AUTOSAR XML (schema 4-0-2)
standard types defined: UINT8, UINT16, UINT32, UINT64, SINT8, SINT16, SINT32, FLOAT32, FLOAT64, dtRef_const_VOID, dtRef_VOID
package /CalDataProvider/ComponentTypes
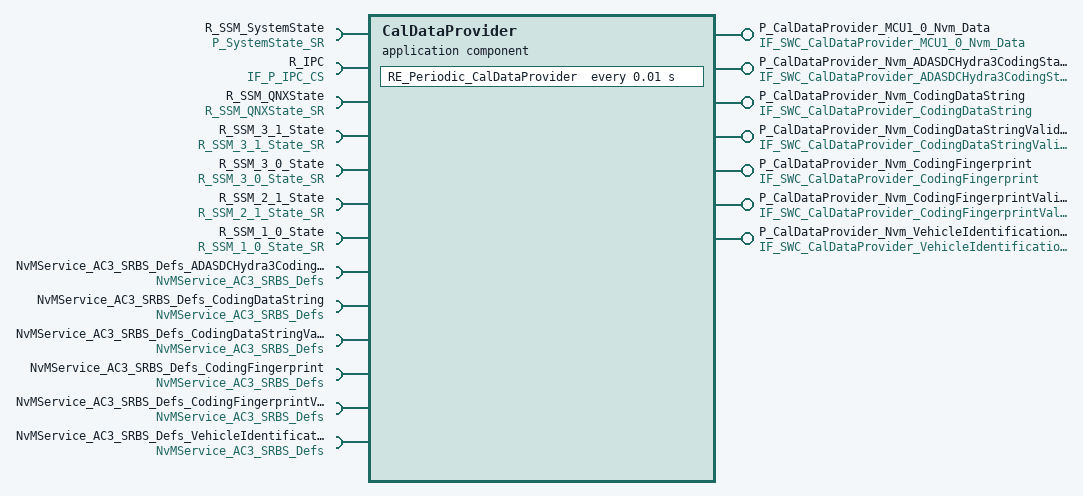
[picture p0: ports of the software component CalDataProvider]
  application sw component type CalDataProvider
    7 x provide port:
      P_CalDataProvider_MCU1_0_Nvm_Data: nonqueued-sender-com-spec{data-element=CalData_mcu1_0, init-value=constant-reference=init_CalData_mcu1_0}, provided-interface=IF_SWC_CalDataProvider_MCU1_0_Nvm_Data
      P_CalDataProvider_Nvm_ADASDCHydra3CodingState: server-com-spec{operation=IF_SWC_CalDataProvider_ADASDCHydra3CodingState/WriteBlock, queue-length=1}, provided-interface=IF_SWC_CalDataProvider_ADASDCHydra3CodingState
      P_CalDataProvider_Nvm_CodingDataString: server-com-spec{operation=IF_SWC_CalDataProvider_CodingDataString/WriteBlock, queue-length=1}, provided-interface=IF_SWC_CalDataProvider_CodingDataString
      P_CalDataProvider_Nvm_CodingDataStringValidation: server-com-spec{operation=IF_SWC_CalDataProvider_CodingDataStringValidation/WriteBlock, queue-length=1}, provided-interface=IF_SWC_CalDataProvider_CodingDataStringValidation
      P_CalDataProvider_Nvm_CodingFingerprint: server-com-spec{operation=IF_SWC_CalDataProvider_CodingFingerprint/WriteBlock, queue-length=1}, provided-interface=IF_SWC_CalDataProvider_CodingFingerprint
      P_CalDataProvider_Nvm_CodingFingerprintValidation: server-com-spec{operation=IF_SWC_CalDataProvider_CodingFingerprintValidation/WriteBlock, queue-length=1}, provided-interface=IF_SWC_CalDataProvider_CodingFingerprintValidation
      P_CalDataProvider_Nvm_VehicleIdentificationNumber: server-com-spec{operation=IF_SWC_CalDataProvider_VehicleIdentificationNumber/WriteBlock, queue-length=1}, provided-interface=IF_SWC_CalDataProvider_VehicleIdentificationNumber
    13 x require port:
      R_SSM_SystemState: nonqueued-receiver-com-spec{data-element=SystemState, init-value=constant-reference=init_SystemState}, required-interface=P_SystemState_SR
      R_IPC: client-com-spec=IPC_Write_v, required-interface=IF_P_IPC_CS
      R_SSM_QNXState: nonqueued-receiver-com-spec{data-element=State_QNX, init-value=constant-reference=init_State_QNX}, required-interface=R_SSM_QNXState_SR
      R_SSM_3_1_State: nonqueued-receiver-com-spec{data-element=State_3_1, init-value=constant-reference=init_State_3_1}, required-interface=R_SSM_3_1_State_SR
      R_SSM_3_0_State: nonqueued-receiver-com-spec{data-element=State_3_0, init-value=constant-reference=init_State_3_0}, required-interface=R_SSM_3_0_State_SR
      R_SSM_2_1_State: required-interface=R_SSM_2_1_State_SR
        required-com-specs:
          data-element=State_2_1, init-value=constant-reference=init_State_2_1
          data-element=State_2_0, init-value=constant-reference=init_State_2_0
      R_SSM_1_0_State: nonqueued-receiver-com-spec{data-element=State_1_0, init-value=constant-reference=init_State_1_0}, required-interface=R_SSM_1_0_State_SR
      NvMService_AC3_SRBS_Defs_ADASDCHydra3CodingState: client-com-spec=NvMService_AC3_SRBS_Defs/WriteBlock, required-interface=NvMService_AC3_SRBS_Defs
      NvMService_AC3_SRBS_Defs_CodingDataString: client-com-spec=NvMService_AC3_SRBS_Defs/WriteBlock, required-interface=NvMService_AC3_SRBS_Defs
      NvMService_AC3_SRBS_Defs_CodingDataStringValidation: client-com-spec=NvMService_AC3_SRBS_Defs/WriteBlock, required-interface=NvMService_AC3_SRBS_Defs
      NvMService_AC3_SRBS_Defs_CodingFingerprint: client-com-spec=NvMService_AC3_SRBS_Defs/WriteBlock, required-interface=NvMService_AC3_SRBS_Defs
      NvMService_AC3_SRBS_Defs_CodingFingerprintValidation: client-com-spec=NvMService_AC3_SRBS_Defs/WriteBlock, required-interface=NvMService_AC3_SRBS_Defs
      NvMService_AC3_SRBS_Defs_VehicleIdentificationNumber: client-com-spec=NvMService_AC3_SRBS_Defs/WriteBlock, required-interface=NvMService_AC3_SRBS_Defs
    behavior CalDataProvider_InternalBehavior: handle-termination-and-restart=NO-SUPPORT
      ar-typed-per-instance-memorys:
        6 x data, all with sw-calibration-access=READ-WRITE:
          ADASDCHydra3CodingState_MirrorBlock: type=UINT8
          CodingDataString_MirrorBlock: type=Dcm_Data256ByteType
          CodingDataStringValidation_MirrorBlock: type=UINT8
          CodingFingerprint_MirrorBlock: type=Dcm_Data30ByteType
          CodingFingerprintValidation_MirrorBlock: type=UINT8
          VehicleIdentificationNumber_MirrorBlock: type=Dcm_Data17ByteType
      timing event TMT_RE_Periodic_CalDataProvider: start-on-event=RE_Periodic_CalDataProvider, period=0.01
      init event InitEvent: start-on-event=RE_CalDataProvider_Init
      6 x operation invoked event:
        OIT_RE_CalDataProvider_Nvm_ADASDCHydra3CodingState_P_CalDataProvider_Nvm_ADASDCHydra3CodingState_WriteBlock: start-on-event=RE_CalDataProvider_Nvm_ADASDCHydra3CodingState, operation=P_CalDataProvider_Nvm_ADASDCHydra3CodingState.WriteBlock
        OIT_RE_CalDataProvider_Nvm_CodingDataString_P_CalDataProvider_Nvm_CodingDataString_WriteBlock: start-on-event=RE_CalDataProvider_Nvm_CodingDataString, operation=P_CalDataProvider_Nvm_CodingDataString.WriteBlock
        OIT_RE_CalDataProvider_Nvm_CodingDataStringValidation_P_CalDataProvider_Nvm_CodingDataStringValidation_WriteBlock: start-on-event=RE_CalDataProvider_Nvm_CodingDataStringValidation, operation=P_CalDataProvider_Nvm_CodingDataStringValidation.WriteBlock
        OIT_RE_CalDataProvider_Nvm_CodingFingerprint_P_CalDataProvider_Nvm_CodingFingerprint_WriteBlock: start-on-event=RE_CalDataProvider_Nvm_CodingFingerprint, operation=P_CalDataProvider_Nvm_CodingFingerprint.WriteBlock
        OIT_RE_CalDataProvider_Nvm_CodingFingerprintValidation_P_CalDataProvider_Nvm_CodingFingerprintValidation_WriteBlock: start-on-event=RE_CalDataProvider_Nvm_CodingFingerprintValidation, operation=P_CalDataProvider_Nvm_CodingFingerprintValidation.WriteBlock
        OIT_RE_CalDataProvider_Nvm_VehicleIdentificationNumber_P_CalDataProvider_Nvm_VehicleIdentificationNumber_WriteBlock: start-on-event=RE_CalDataProvider_Nvm_VehicleIdentificationNumber, operation=P_CalDataProvider_Nvm_VehicleIdentificationNumber.WriteBlock
      port-api-options:
        enable-take-address=false, indirect-api=false, port=NvMService_AC3_SRBS_Defs_ADASDCHydra3CodingState
        enable-take-address=false, indirect-api=false, port=NvMService_AC3_SRBS_Defs_CodingDataString
        enable-take-address=false, indirect-api=false, port=NvMService_AC3_SRBS_Defs_CodingDataStringValidation
        enable-take-address=false, indirect-api=false, port=NvMService_AC3_SRBS_Defs_CodingFingerprint
        enable-take-address=false, indirect-api=false, port=NvMService_AC3_SRBS_Defs_CodingFingerprintValidation
        enable-take-address=false, indirect-api=false, port=NvMService_AC3_SRBS_Defs_VehicleIdentificationNumber
        enable-take-address=false, indirect-api=false, port=P_CalDataProvider_MCU1_0_Nvm_Data
        enable-take-address=false, indirect-api=false, port=P_CalDataProvider_Nvm_ADASDCHydra3CodingState
        enable-take-address=false, indirect-api=false, port=P_CalDataProvider_Nvm_CodingDataString
        enable-take-address=false, indirect-api=false, port=P_CalDataProvider_Nvm_CodingDataStringValidation
        enable-take-address=false, indirect-api=false, port=P_CalDataProvider_Nvm_CodingFingerprint
        enable-take-address=false, indirect-api=false, port=P_CalDataProvider_Nvm_CodingFingerprintValidation
        enable-take-address=false, indirect-api=false, port=P_CalDataProvider_Nvm_VehicleIdentificationNumber
        enable-take-address=false, indirect-api=false, port=R_IPC
        enable-take-address=false, indirect-api=false, port=R_SSM_1_0_State
        enable-take-address=false, indirect-api=false, port=R_SSM_2_1_State
        enable-take-address=false, indirect-api=false, port=R_SSM_3_0_State
        enable-take-address=false, indirect-api=false, port=R_SSM_3_1_State
        enable-take-address=false, indirect-api=false, port=R_SSM_QNXState
        enable-take-address=false, indirect-api=false, port=R_SSM_SystemState
      8 x runnable:
        RE_Periodic_CalDataProvider  # Periodic Runnable of Satellite
          data-receive-point-by-arguments:
            7 x access:
              REC_R_SSM_SystemState_SystemState: accessed-variable=R_SSM_SystemState.SystemState
              REC_R_SSM_QNXState_State_QNX: accessed-variable=R_SSM_QNXState.State_QNX
              REC_R_SSM_3_1_State_State_3_1: accessed-variable=R_SSM_3_1_State.State_3_1
              REC_R_SSM_3_0_State_State_3_0: accessed-variable=R_SSM_3_0_State.State_3_0
              REC_R_SSM_2_1_State_State_2_1: accessed-variable=R_SSM_2_1_State.State_2_1
              REC_R_SSM_2_1_State_State_2_0: accessed-variable=R_SSM_2_1_State.State_2_0
              REC_R_SSM_1_0_State_State_1_0: accessed-variable=R_SSM_1_0_State.State_1_0
          data-send-points:
            access SEND_P_CalDataProvider_MCU1_0_Nvm_Data_CalData_mcu1_0: accessed-variable=P_CalDataProvider_MCU1_0_Nvm_Data.CalData_mcu1_0
          6 x parameter access:
            PA_ADASDCHydra3CodingState_DefaultValue: accessed-parameter=ADASDCHydra3CodingState_DefaultValue
            PA_CodingDataString_DefaultValue: accessed-parameter=CodingDataString_DefaultValue
            PA_CodingDataStringValidation_DefaultValue: accessed-parameter=CodingDataStringValidation_DefaultValue
            PA_CodingFingerprint_DefaultValue: accessed-parameter=CodingFingerprint_DefaultValue
            PA_CodingFingerprintValidation_DefaultValue: accessed-parameter=CodingFingerprintValidation_DefaultValue
            PA_VehicleIdentificationNumber_DefaultValue: accessed-parameter=VehicleIdentificationNumber_DefaultValue
          sync call SC_R_IPC_IPC_Write_v: operation=R_IPC.IPC_Write_v, timeout=0
        RE_CalDataProvider_Init
          6 x parameter access:
            PA_ADASDCHydra3CodingState_DefaultValue: accessed-parameter=ADASDCHydra3CodingState_DefaultValue
            PA_CodingDataString_DefaultValue: accessed-parameter=CodingDataString_DefaultValue
            PA_CodingDataStringValidation_DefaultValue: accessed-parameter=CodingDataStringValidation_DefaultValue
            PA_CodingFingerprint_DefaultValue: accessed-parameter=CodingFingerprint_DefaultValue
            PA_CodingFingerprintValidation_DefaultValue: accessed-parameter=CodingFingerprintValidation_DefaultValue
            PA_VehicleIdentificationNumber_DefaultValue: accessed-parameter=VehicleIdentificationNumber_DefaultValue
        RE_CalDataProvider_Nvm_ADASDCHydra3CodingState
          6 x parameter access:
            PA_ADASDCHydra3CodingState_DefaultValue: accessed-parameter=ADASDCHydra3CodingState_DefaultValue
            PA_CodingDataString_DefaultValue: accessed-parameter=CodingDataString_DefaultValue
            PA_CodingDataStringValidation_DefaultValue: accessed-parameter=CodingDataStringValidation_DefaultValue
            PA_CodingFingerprint_DefaultValue: accessed-parameter=CodingFingerprint_DefaultValue
            PA_CodingFingerprintValidation_DefaultValue: accessed-parameter=CodingFingerprintValidation_DefaultValue
            PA_VehicleIdentificationNumber_DefaultValue: accessed-parameter=VehicleIdentificationNumber_DefaultValue
        RE_CalDataProvider_Nvm_CodingDataString
          6 x parameter access:
            PA_ADASDCHydra3CodingState_DefaultValue: accessed-parameter=ADASDCHydra3CodingState_DefaultValue
            PA_CodingDataString_DefaultValue: accessed-parameter=CodingDataString_DefaultValue
            PA_CodingDataStringValidation_DefaultValue: accessed-parameter=CodingDataStringValidation_DefaultValue
            PA_CodingFingerprint_DefaultValue: accessed-parameter=CodingFingerprint_DefaultValue
            PA_CodingFingerprintValidation_DefaultValue: accessed-parameter=CodingFingerprintValidation_DefaultValue
            PA_VehicleIdentificationNumber_DefaultValue: accessed-parameter=VehicleIdentificationNumber_DefaultValue
        RE_CalDataProvider_Nvm_CodingDataStringValidation
          6 x parameter access:
            PA_ADASDCHydra3CodingState_DefaultValue: accessed-parameter=ADASDCHydra3CodingState_DefaultValue
            PA_CodingDataString_DefaultValue: accessed-parameter=CodingDataString_DefaultValue
            PA_CodingDataStringValidation_DefaultValue: accessed-parameter=CodingDataStringValidation_DefaultValue
            PA_CodingFingerprint_DefaultValue: accessed-parameter=CodingFingerprint_DefaultValue
            PA_CodingFingerprintValidation_DefaultValue: accessed-parameter=CodingFingerprintValidation_DefaultValue
            PA_VehicleIdentificationNumber_DefaultValue: accessed-parameter=VehicleIdentificationNumber_DefaultValue
        RE_CalDataProvider_Nvm_CodingFingerprint
          6 x parameter access:
            PA_ADASDCHydra3CodingState_DefaultValue: accessed-parameter=ADASDCHydra3CodingState_DefaultValue
            PA_CodingDataString_DefaultValue: accessed-parameter=CodingDataString_DefaultValue
            PA_CodingDataStringValidation_DefaultValue: accessed-parameter=CodingDataStringValidation_DefaultValue
            PA_CodingFingerprint_DefaultValue: accessed-parameter=CodingFingerprint_DefaultValue
            PA_CodingFingerprintValidation_DefaultValue: accessed-parameter=CodingFingerprintValidation_DefaultValue
            PA_VehicleIdentificationNumber_DefaultValue: accessed-parameter=VehicleIdentificationNumber_DefaultValue
        RE_CalDataProvider_Nvm_CodingFingerprintValidation
          6 x parameter access:
            PA_ADASDCHydra3CodingState_DefaultValue: accessed-parameter=ADASDCHydra3CodingState_DefaultValue
            PA_CodingDataString_DefaultValue: accessed-parameter=CodingDataString_DefaultValue
            PA_CodingDataStringValidation_DefaultValue: accessed-parameter=CodingDataStringValidation_DefaultValue
            PA_CodingFingerprint_DefaultValue: accessed-parameter=CodingFingerprint_DefaultValue
            PA_CodingFingerprintValidation_DefaultValue: accessed-parameter=CodingFingerprintValidation_DefaultValue
            PA_VehicleIdentificationNumber_DefaultValue: accessed-parameter=VehicleIdentificationNumber_DefaultValue
        RE_CalDataProvider_Nvm_VehicleIdentificationNumber
          6 x parameter access:
            PA_ADASDCHydra3CodingState_DefaultValue: accessed-parameter=ADASDCHydra3CodingState_DefaultValue
            PA_CodingDataString_DefaultValue: accessed-parameter=CodingDataString_DefaultValue
            PA_CodingDataStringValidation_DefaultValue: accessed-parameter=CodingDataStringValidation_DefaultValue
            PA_CodingFingerprint_DefaultValue: accessed-parameter=CodingFingerprint_DefaultValue
            PA_CodingFingerprintValidation_DefaultValue: accessed-parameter=CodingFingerprintValidation_DefaultValue
            PA_VehicleIdentificationNumber_DefaultValue: accessed-parameter=VehicleIdentificationNumber_DefaultValue
      6 x swc service dependency:
        ADASDCHydra3CodingState: assigned-ports=role-based-port-assignment={port-prototype=NvMService_AC3_SRBS_Defs_ADASDCHydra3CodingState, role=NvMService_AC3_SRBS_Defs_ADASDCHydra3CodingState}
          assigned-datas:
            role=ramBlock, used-data-element=ADASDCHydra3CodingState_MirrorBlock
            role=defaultValue, used-parameter-element=ADASDCHydra3CodingState_DefaultValue
          service-needs:
            nv block needs ADASDCHydra3CodingState: calc-ram-block-crc=true, check-static-block-id=false, n-data-sets=0, ram-block-status-control=API, readonly=false, reliability=NO-PROTECTION, resistant-to-changed-sw=true, restore-at-start=true, store-at-shutdown=true, store-cyclic=false, store-emergency=false, store-immediate=false, use-auto-validation-at-shut-down=false, use-crc-comp-mechanism=true, write-only-once=false, write-verification=false
        CodingDataString: assigned-ports=role-based-port-assignment={port-prototype=NvMService_AC3_SRBS_Defs_CodingDataString, role=NvMService_AC3_SRBS_Defs_CodingDataString}
          assigned-datas:
            role=ramBlock, used-data-element=CodingDataString_MirrorBlock
            role=defaultValue, used-parameter-element=CodingDataString_DefaultValue
          service-needs:
            nv block needs CodingDataString: calc-ram-block-crc=true, check-static-block-id=false, n-data-sets=0, ram-block-status-control=API, readonly=false, reliability=NO-PROTECTION, resistant-to-changed-sw=true, restore-at-start=true, store-at-shutdown=true, store-cyclic=false, store-emergency=false, store-immediate=false, use-auto-validation-at-shut-down=false, use-crc-comp-mechanism=true, write-only-once=false, write-verification=false
        CodingDataStringValidation: assigned-ports=role-based-port-assignment={port-prototype=NvMService_AC3_SRBS_Defs_CodingDataStringValidation, role=NvMService_AC3_SRBS_Defs_CodingDataStringValidation}
          assigned-datas:
            role=ramBlock, used-data-element=CodingDataStringValidation_MirrorBlock
            role=defaultValue, used-parameter-element=CodingDataStringValidation_DefaultValue
          service-needs:
            nv block needs CodingDataStringValidation: calc-ram-block-crc=true, check-static-block-id=false, n-data-sets=0, ram-block-status-control=API, readonly=false, reliability=NO-PROTECTION, resistant-to-changed-sw=true, restore-at-start=true, store-at-shutdown=true, store-cyclic=false, store-emergency=false, store-immediate=false, use-auto-validation-at-shut-down=false, use-crc-comp-mechanism=true, write-only-once=false, write-verification=false
        CodingFingerprint: assigned-ports=role-based-port-assignment={port-prototype=NvMService_AC3_SRBS_Defs_CodingFingerprint, role=NvMService_AC3_SRBS_Defs_CodingFingerprint}
          assigned-datas:
            role=ramBlock, used-data-element=CodingFingerprint_MirrorBlock
            role=defaultValue, used-parameter-element=CodingFingerprint_DefaultValue
          service-needs:
            nv block needs CodingFingerprint: calc-ram-block-crc=true, check-static-block-id=false, n-data-sets=0, ram-block-status-control=API, readonly=false, reliability=NO-PROTECTION, resistant-to-changed-sw=true, restore-at-start=true, store-at-shutdown=true, store-cyclic=false, store-emergency=false, store-immediate=false, use-auto-validation-at-shut-down=false, use-crc-comp-mechanism=true, write-only-once=false, write-verification=false
        CodingFingerprintValidation: assigned-ports=role-based-port-assignment={port-prototype=NvMService_AC3_SRBS_Defs_CodingFingerprintValidation, role=NvMService_AC3_SRBS_Defs_CodingFingerprintValidation}
          assigned-datas:
            role=ramBlock, used-data-element=CodingFingerprintValidation_MirrorBlock
            role=defaultValue, used-parameter-element=CodingFingerprintValidation_DefaultValue
          service-needs:
            nv block needs CodingFingerprintValidation: calc-ram-block-crc=true, check-static-block-id=false, n-data-sets=0, ram-block-status-control=API, readonly=false, reliability=NO-PROTECTION, resistant-to-changed-sw=true, restore-at-start=true, store-at-shutdown=true, store-cyclic=false, store-emergency=false, store-immediate=false, use-auto-validation-at-shut-down=false, use-crc-comp-mechanism=true, write-only-once=false, write-verification=false
        VehicleIdentificationNumber: assigned-ports=role-based-port-assignment={port-prototype=NvMService_AC3_SRBS_Defs_VehicleIdentificationNumber, role=NvMService_AC3_SRBS_Defs_VehicleIdentificationNumber}
          assigned-datas:
            role=ramBlock, used-data-element=VehicleIdentificationNumber_MirrorBlock
            role=defaultValue, used-parameter-element=VehicleIdentificationNumber_DefaultValue
          service-needs:
            nv block needs VehicleIdentificationNumber: calc-ram-block-crc=true, check-static-block-id=false, n-data-sets=0, ram-block-status-control=API, readonly=false, reliability=NO-PROTECTION, resistant-to-changed-sw=true, restore-at-start=true, store-at-shutdown=true, store-cyclic=false, store-emergency=false, store-immediate=false, use-auto-validation-at-shut-down=false, use-crc-comp-mechanism=true, write-only-once=false, write-verification=false
      shared-parameters:
        6 x parameter data prototype, all with sw-calibration-access=READ-ONLY:
          ADASDCHydra3CodingState_DefaultValue: type=UINT8, init-value=0
          CodingDataString_DefaultValue: type=Dcm_Data256ByteType, init-value=[0, 0, 0, 0, 0, 0, 0, 0, 0, 0, 0, 0, 1, 0, 1, 1, 0, 1, 1, 0, 0, 0, 1, 0, 1, 1, 1, 0, 0, 0, 0, 0, 0, 0, 0, 0, 0, 0, 0, 0, 0, 0, 0, 0, 0, 0, 22, 99, 8, 40, 0, 0, 0, 20, 0, 0, 0, 0, 0, 0, 0, 0, 0, 0, 0, 0, 0, 0, 0, 0, 0, 0, 0, 0, 0, 0, 0, 0, 0, 0, 0, 0, 0, 0, 0, 0, 0, 0, 0, 0, 0, 0, 0, 0, 0, 0, 0, 0, 0, 0, 0, 0, 0, 0, 0, 0, 0, 0, 0, 0, 0, 0, 0, 0, 0, 0, 0, 0, 0, 0, 0, 0, 0, 0, 0, 0, 0, 0, 0, 0, 0, 0, 0, 0, 0, 0, 0, 0, 0, 0, 0, 0, 0, 0, 0, 0, 0, 0, 0, 0, 0, 0, 0, 0, 0, 0, 0, 0, 0, 0, 0, 0, 0, 0, 0, 0, 0, 0, 0, 0, 0, 0, 0, 0, 0, 0, 0, 0, 0, 0, 0, 0, 0, 0, 0, 0, 0, 0, 0, 0, 0, 0, 0, 0, 0, 0, 0, 0, 0, 0, 0, 0, 0, 0, 0, 0, 0, 0, 0, 0, 0, 0, 0, 0, 0, 0, 0, 0, 0, 0, 0, 0, 0, 0, 0, 0, 0, 0, 0, 0, 0, 0, 0, 0, 0, 0, 0, 0, 0, 0, 0, 0, 0, 0, 0, 0, 0, 0, 0, 0, 0, 0, 0, 0, 0, 0]
          CodingDataStringValidation_DefaultValue: type=UINT8, init-value=0
          CodingFingerprint_DefaultValue: type=Dcm_Data30ByteType, init-value=30 x 0
          CodingFingerprintValidation_DefaultValue: type=UINT8, init-value=0
          VehicleIdentificationNumber_DefaultValue: type=Dcm_Data17ByteType, init-value=17 x 0
  swc implementation CalDataProvider_Implementation: programming-language=C, vendor-id=0, behavior=CalDataProvider_InternalBehavior
    code-descriptors:
      code Default: artifact-descriptors=autosar-engineering-object={short-label=Default, category=SWSRC}
package /CalDataProvider/Constant
  7 x constant specification:
    init_CalData_mcu1_0: value-spec=fields=[0, 0, [0, 0, 0, 0, 0, 0, 0, 0, 0, 0, 0, 0, 1, 0, 1, 1, 0, 1, 1, 0, 0, 0, 1, 0, 1, 1, 1, 0, 0, 0, 0, 0, 0, 0, 0, 0, 0, 0, 0, 0, 0, 0, 0, 0, 0, 0, 22, 99, 8, 40, 0, 0, 0, 20, 0, 0, 0, 0, 0, 0, 0, 0, 0, 0, 0, 0, 0, 0, 0, 0, 0, 0, 0, 0, 0, 0, 0, 0, 0, 0, 0, 0, 0, 0, 0, 0, 0, 0, 0, 0, 0, 0, 0, 0, 0, 0, 0, 0, 0, 0, 0, 0, 0, 0, 0, 0, 0, 0, 0, 0, 0, 0, 0, 0, 0, 0, 0, 0, 0, 0, 0, 0, 0, 0, 0, 0, 0, 0, 0, 0, 0, 0, 0, 0, 0, 0, 0, 0, 0, 0, 0, 0, 0, 0, 0, 0, 0, 0, 0, 0, 0, 0, 0, 0, 0, 0, 0, 0, 0, 0, 0, 0, 0, 0, 0, 0, 0, 0, 0, 0, 0, 0, 0, 0, 0, 0, 0, 0, 0, 0, 0, 0, 0, 0, 0, 0, 0, 0, 0, 0, 0, 0, 0, 0, 0, 0, 0, 0, 0, 0, 0, 0, 0, 0, 0, 0, 0, 0, 0, 0, 0, 0, 0, 0, 0, 0, 0, 0, 0, 0, 0, 0, 0, 0, 0, 0, 0, 0, 0, 0, 0, 0, 0, 0, 0, 0, 0, 0, 0, 0, 0, 0, 0, 0, 0, 0, 0, 0, 0, 0, 0, 0, 0, 0, 0, 0], 0, 30 x 0, 0, 17 x 0, 0]
    init_State_QNX: value-spec=fields=[0, [0, 0, 0]]
    init_State_3_1: value-spec=fields=[0, [0, 0]]
    init_State_3_0: value-spec=fields=[0, [0, 0]]
    init_State_2_1: value-spec=fields=[0, 6 x 0]
    init_State_2_0: value-spec=fields=[0, [0, 0]]
    init_State_1_0: value-spec=fields=[0, [0, 0, 0]]
package /CalDataProvider/ImplementationDataTypes
  28 x impl type, all with type-emitter=RTE:
    BOOL: implementation-data-type=boolean
    SSM_CoreSlaveCoreStateDef: compu {0=SSM_SlaveCore_State_Unknown, 1=SSM_SlaveCore_State_BSP_Booting, 2=SSM_SlaveCore_State_BSP_Init_Done, 3=SSM_SlaveCore_State_Calibrated, 4=SSM_SlaveCore_State_AppInitialized, 5=SSM_SlaveCore_State_Running, 6=SSM_SlaveCore_State_MAX}, implementation-data-type=uint32
    SSM_SystemStateDef: compu {0=SSM_STATE_BOOTING, 1=SSM_STATE_IPCREADY, 2=SSM_STATE_RUNNING, 3=SSM_STATE_DEGRADED, 4=SSM_STATE_POWERINGDOWN, 5=SSM_STATE_OFF, 6=SSM_STATE_MAX}, implementation-data-type=uint32
    SSM_DegradedState: compu {0=SSM_DEGRADEDSTATE_MAX}, implementation-data-type=uint32
    SSM_ApplicationStatus: compu {0=SSM_APPSTATE_UNINIT, 1=SSM_APPSTATE_INIT, 2=SSM_APPSTATE_RUNNING, 3=SSM_APPSTATE_DEGRADED, 4=SSM_APPSTATE_STOPPED, 5=SSM_APPSTATE_MAX}, implementation-data-type=uint32
    SSM_MCU_QNX_Applications: compu {0=SSM_MCU_QNX_Application_ErrorMgr, 1=SSM_MCU_QNX_Application_PLD, 2=SSM_MCU_QNX_Application_MAX}, implementation-data-type=uint32
    SSM_MCU_3_1_Applications: compu {0=SSM_MCU_3_1_Application_ErrorMgr, 1=SSM_MCU_3_1_Application_MAX}, implementation-data-type=uint32
    SSM_MCU_3_0_Applications: compu {0=SSM_MCU_3_0_Application_ErrorMgr, 1=SSM_MCU_3_0_Application_USS, 2=SSM_MCU_3_0_Application_APA, 3=SSM_MCU_3_0_Application_CD, 4=SSM_MCU_3_0_Application_FUSION, 5=SSM_MCU_3_0_Application_MAX}, implementation-data-type=uint32
    SSM_MCU_2_1_Applications: compu {0=SSM_MCU_2_1_Application_ErrorMgr, 1=SSM_MCU_2_1_Application_HSF, 2=SSM_MCU_2_1_Application_KM, 3=SSM_MCU_2_1_Application_APStateMachine, 4=SSM_MCU_2_1_Application_DMS, 5=SSM_MCU_2_1_Application_MAX}, implementation-data-type=uint32
    SSM_MCU_2_0_Applications: compu {0=SSM_MCU_2_0_Application_ErrorMgr, 1=SSM_MCU_2_0_Application_MAX}, implementation-data-type=uint32
    SSM_MCU_1_0_Applications: compu {0=SSM_MCU_1_0_Application_VehInpAdapter, 1=SSM_MCU_1_0_Application_VehOptAdapter, 2=SSM_MCU_1_0_Application_MAX}, implementation-data-type=uint32
    SSM_MCU_QNX_LocalAppStatus_Arr: category=ARRAY
      element Elem_SSM_ApplicationStatus: array-size=3, array-size-semantics=FIXED-SIZE, implementation-data-type=SSM_ApplicationStatus
    SSM_MCU_3_1_LocalAppStatus_Arr: category=ARRAY
      element Elem_SSM_ApplicationStatus: array-size=2, array-size-semantics=FIXED-SIZE, implementation-data-type=SSM_ApplicationStatus
    SSM_MCU_3_0__LocalAppStatus_Arr: category=ARRAY
      element Elem_SSM_ApplicationStatus: array-size=6, array-size-semantics=FIXED-SIZE, implementation-data-type=SSM_ApplicationStatus
    SSM_MCU_2_1_LocalAppStatus_Arr: category=ARRAY
      element Elem_SSM_ApplicationStatus: array-size=6, array-size-semantics=FIXED-SIZE, implementation-data-type=SSM_ApplicationStatus
    SSM_MCU_2_0_LocalAppStatus_Arr: category=ARRAY
      element Elem_SSM_ApplicationStatus: array-size=2, array-size-semantics=FIXED-SIZE, implementation-data-type=SSM_ApplicationStatus
    SSM_MCU_1_0_LocalAppStatus_Arr: category=ARRAY
      element Elem_SSM_ApplicationStatus: array-size=3, array-size-semantics=FIXED-SIZE, implementation-data-type=SSM_ApplicationStatus
    SSM_QNX_CoreStatus: category=STRUCTURE
      element CoreStatus: implementation-data-type=SSM_CoreSlaveCoreStateDef
      element LocalAppStatus: implementation-data-type=SSM_MCU_QNX_LocalAppStatus_Arr
    SSM_3_1_CoreStatus: category=STRUCTURE
      element CoreStatus: implementation-data-type=SSM_CoreSlaveCoreStateDef
      element LocalAppStatus: implementation-data-type=SSM_MCU_3_1_LocalAppStatus_Arr
    SSM_3_0_CoreStatus: category=STRUCTURE
      element CoreStatus: implementation-data-type=SSM_CoreSlaveCoreStateDef
      element LocalAppStatus: implementation-data-type=SSM_MCU_2_0_LocalAppStatus_Arr
    SSM_2_1_CoreStatus: category=STRUCTURE
      element CoreStatus: implementation-data-type=SSM_CoreSlaveCoreStateDef
      element LocalAppStatus: implementation-data-type=SSM_MCU_2_1_LocalAppStatus_Arr
    SSM_2_0_CoreStatus: category=STRUCTURE
      element CoreStatus: implementation-data-type=SSM_CoreSlaveCoreStateDef
      element LocalAppStatus: implementation-data-type=SSM_MCU_2_0_LocalAppStatus_Arr
    SSM_1_0_CoreStatus: category=STRUCTURE
      element CoreStatus: implementation-data-type=SSM_CoreSlaveCoreStateDef
      element LocalAppStatus: implementation-data-type=SSM_MCU_1_0_LocalAppStatus_Arr
    CalDataProvider_MCU_1_0_Def: category=STRUCTURE
      8 x element, all with category=TYPE_REFERENCE:
        FreshnessCount: implementation-data-type=UINT32
        CalData_ADASDCHydra3CodingState: implementation-data-type=UINT8
        CalData_CodingDataString: implementation-data-type=Dcm_Data256ByteType
        CalData_CodingDataStringValidation: implementation-data-type=UINT8
        CalData_CodingFingerprint: implementation-data-type=Dcm_Data30ByteType
        CalData_CodingFingerprintValidation: implementation-data-type=UINT8
        CalData_VehicleIdentificationNumber: implementation-data-type=Dcm_Data17ByteType
        bValid: implementation-data-type=BOOL
    Dcm_Data17ByteType: category=ARRAY
      element Elem_UINT8: array-size=17, array-size-semantics=FIXED-SIZE, implementation-data-type=UINT8
    Dcm_Data30ByteType: category=ARRAY
      element Elem_UINT8: array-size=30, array-size-semantics=FIXED-SIZE, implementation-data-type=UINT8
    Dcm_Data256ByteType: category=ARRAY
      element Elem_UINT8: array-size=256, array-size-semantics=FIXED-SIZE, implementation-data-type=UINT8
    NvM_RequestResultType: compu {0=NVM_REQ_OK, 1=NVM_REQ_NOT_OK, 2=NVM_REQ_PENDING, 3=NVM_REQ_INTEGRITY_FAILED, 4=NVM_REQ_BLOCK_SKIPPED, 5=NVM_REQ_NV_INVALIDATED, 6=NVM_REQ_CANCELED, 7=NVM_REQ_REDUNDANCY_FAILED, 8=NVM_REQ_RESTORED_FROM_ROM}, implementation-data-type=UINT8
package /CalDataProvider/PortInterfaces
  7 x client server interface:
    IF_SWC_CalDataProvider_ADASDCHydra3CodingState
      operation WriteBlock: possible-error=IF_SWC_CalDataProvider_ADASDCHydra3CodingState/E_NOT_OK
        arg v_ADASDCHydra3CodingState: type=UINT8, direction=IN, server-argument-impl-policy=USE-ARGUMENT-TYPE
      error E_NOT_OK: error-code=1
    IF_SWC_CalDataProvider_CodingDataString
      operation WriteBlock: possible-error=IF_SWC_CalDataProvider_CodingDataString/E_NOT_OK
        arg v_CodingDataString: type=Dcm_Data256ByteType, direction=IN, server-argument-impl-policy=USE-ARGUMENT-TYPE
      error E_NOT_OK: error-code=1
    IF_SWC_CalDataProvider_CodingDataStringValidation
      operation WriteBlock: possible-error=IF_SWC_CalDataProvider_CodingDataStringValidation/E_NOT_OK
        arg v_CodingDataStringValidation: type=UINT8, direction=IN, server-argument-impl-policy=USE-ARGUMENT-TYPE
      error E_NOT_OK: error-code=1
    IF_SWC_CalDataProvider_CodingFingerprint
      operation WriteBlock: possible-error=IF_SWC_CalDataProvider_CodingFingerprint/E_NOT_OK
        arg v_CodingFingerprint: type=Dcm_Data30ByteType, direction=IN, server-argument-impl-policy=USE-ARGUMENT-TYPE
      error E_NOT_OK: error-code=1
    IF_SWC_CalDataProvider_CodingFingerprintValidation
      operation WriteBlock: possible-error=IF_SWC_CalDataProvider_CodingFingerprintValidation/E_NOT_OK
        arg v_CodingFingerprintValidation: type=UINT8, direction=IN, server-argument-impl-policy=USE-ARGUMENT-TYPE
      error E_NOT_OK: error-code=1
    IF_SWC_CalDataProvider_VehicleIdentificationNumber
      operation WriteBlock: possible-error=IF_SWC_CalDataProvider_VehicleIdentificationNumber/E_NOT_OK
        arg v_VehicleIdentificationNumber: type=Dcm_Data17ByteType, direction=IN, server-argument-impl-policy=USE-ARGUMENT-TYPE
      error E_NOT_OK: error-code=1
    NvMService_AC3_SRBS_Defs: is-service=true
      7 x operation, all with possible-error=NvMService_AC3_SRBS_Defs/E_NOT_OK:
        WriteBlock
          arg SrcPtr: type=dtRef_const_VOID, direction=IN, server-argument-impl-policy=USE-ARGUMENT-TYPE
        EraseBlock
        GetErrorStatus
          arg ErrorStatus: type=NvM_RequestResultType, direction=OUT, server-argument-impl-policy=USE-ARGUMENT-TYPE
        InvalidateNvBlock
        ReadBlock
          arg DstPtr: type=dtRef_VOID, direction=IN, server-argument-impl-policy=USE-ARGUMENT-TYPE
        RestoreBlockDefaults
          arg DstPtr: type=dtRef_VOID, direction=IN, server-argument-impl-policy=USE-ARGUMENT-TYPE
        SetRamBlockStatus
          arg RamBlockStatus: type=BOOL, direction=IN, server-argument-impl-policy=USE-ARGUMENT-TYPE
      error E_NOT_OK: error-code=1
  6 x sender receiver interface:
    R_SSM_QNXState_SR  # Input
      data State_QNX: type=SSM_QNX_CoreStatus
    R_SSM_3_1_State_SR  # Input
      data State_3_1: type=SSM_3_1_CoreStatus
    R_SSM_3_0_State_SR  # Input
      data State_3_0: type=SSM_3_0_CoreStatus
    R_SSM_2_1_State_SR  # Input
      data State_2_1: type=SSM_2_1_CoreStatus
      data State_2_0: type=SSM_2_0_CoreStatus
    R_SSM_1_0_State_SR  # Input
      data State_1_0: type=SSM_1_0_CoreStatus
    IF_SWC_CalDataProvider_MCU1_0_Nvm_Data
      data CalData_mcu1_0: type=CalDataProvider_MCU_1_0_Def
